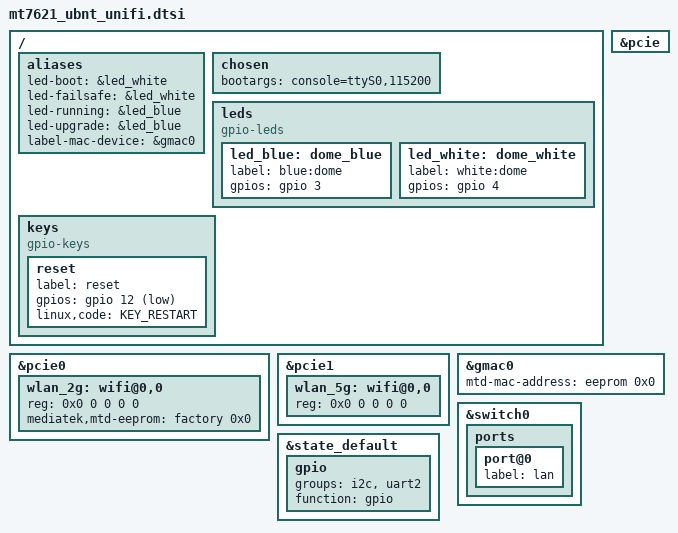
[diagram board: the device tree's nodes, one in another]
// SPDX-License-Identifier: GPL-2.0-or-later OR MIT

#include "mt7621.dtsi"

#include <dt-bindings/gpio/gpio.h>
#include <dt-bindings/input/input.h>

/ {
	aliases {
		led-boot = &led_white;
		led-failsafe = &led_white;
		led-running = &led_blue;
		led-upgrade = &led_blue;
		label-mac-device = &gmac0;
	};

	chosen {
		bootargs = "console=ttyS0,115200";
	};

	leds {
		compatible = "gpio-leds";

		led_blue: dome_blue {
			label = "blue:dome";
			gpios = <&gpio 3 GPIO_ACTIVE_HIGH>;
		};

		led_white: dome_white {
			label = "white:dome";
			gpios = <&gpio 4 GPIO_ACTIVE_HIGH>;
		};
	};

	keys {
		compatible = "gpio-keys";

		reset {
			label = "reset";
			gpios = <&gpio 12 GPIO_ACTIVE_LOW>;
			linux,code = <KEY_RESTART>;
		};
	};
};

&pcie {
	status = "okay";
};

&pcie0 {
	wlan_2g: wifi@0,0 {
		reg = <0x0 0 0 0 0>;
		mediatek,mtd-eeprom = <&factory 0x0>;
	};
};

&pcie1 {
	wlan_5g: wifi@0,0 {
		reg = <0x0 0 0 0 0>;
	};
};

&gmac0 {
	mtd-mac-address = <&eeprom 0x0>;
};

&switch0 {
	ports {
		port@0 {
			status = "okay";
			label = "lan";
		};
	};
};

&state_default {
	gpio {
		groups = "i2c", "uart2";
		function = "gpio";
	};
};
